# CY8C5888LTI_LP097 register map
File version: 0.1
Registers are 8-bit, read-write, no defined reset value unless marked. A register's access mark holds for its fields unless they carry their own. Offsets are from the block's base; [hi:lo] are bit positions; 'fields as' and 'values as' point back to an identical list.

## PWM_MOTORS
Base 0x00000000
0x40006428 PWM_MOTORS__COMPARE1 — UDB.D0 - Assigned Compare1 Value
0x40006438 PWM_MOTORS__COMPARE2 — UDB.D1 - Assigned Compare2 Value
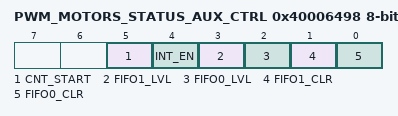
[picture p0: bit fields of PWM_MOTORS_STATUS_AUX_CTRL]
0x40006498 PWM_MOTORS_STATUS_AUX_CTRL — UDB Auxilliary Control Register
  [5] CNT_START — FIFO0 clear
    0=E_CNT_START0 (Disable counter); 1=E_CNT_START1 (Enable counter)
  [4] INT_EN
    0=E_INT_EN0 (Interrupt disabled); 1=E_INT_EN1 (Interrupt enabled)
  [3] FIFO1_LVL — FIFO level
    0=E_FIFO_LVL_0 (FIFO LVL: input mode: FIFO not full; output mode: FIFO not empty); 1=E_FIFO_LVL_1 (FIFO LVL: input mode: FIFO at least 1/2 empty; output mode: FIFO at least 1/2 full)
  [2] FIFO0_LVL — FIFO level
    values as FIFO1_LVL
  [1] FIFO1_CLR — FIFO1 clear
    0=E_FIFO_CLR_0 (Normal FIFO operation); 1=E_FIFO_CLR_1 (Clear FIFO state)
  [0] FIFO0_CLR — FIFO0 clear
    values as FIFO1_CLR

## BLINK_05HZ
Base 0x00000000
0x40006422 BLINK_05HZ_COMPARE_Reg 16-bit — UDB.D0 - Assigned Compare Value
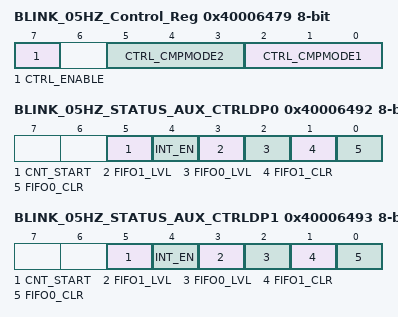
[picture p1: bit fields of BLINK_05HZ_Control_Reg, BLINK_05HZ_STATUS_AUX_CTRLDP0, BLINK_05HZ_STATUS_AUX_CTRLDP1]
0x40006479 BLINK_05HZ_Control_Reg — UDB Control Register - Assigned Control Register Value
  [7] CTRL_ENABLE — Enable the PWM
  [5:3] CTRL_CMPMODE2 — Compare mode 2
  [2:0] CTRL_CMPMODE1 — Compare mode 1
0x40006492 BLINK_05HZ_STATUS_AUX_CTRLDP0 — UDB Auxilliary Control Register
  [5] CNT_START — FIFO0 clear
    0=E_CNT_START0 (Disable counter); 1=E_CNT_START1 (Enable counter)
  [4] INT_EN
    0=E_INT_EN0 (Interrupt disabled); 1=E_INT_EN1 (Interrupt enabled)
  [3] FIFO1_LVL — FIFO level
    0=E_FIFO_LVL_0 (FIFO LVL: input mode: FIFO not full; output mode: FIFO not empty); 1=E_FIFO_LVL_1 (FIFO LVL: input mode: FIFO at least 1/2 empty; output mode: FIFO at least 1/2 full)
  [2] FIFO0_LVL — FIFO level
    values as FIFO1_LVL
  [1] FIFO1_CLR — FIFO1 clear
    0=E_FIFO_CLR_0 (Normal FIFO operation); 1=E_FIFO_CLR_1 (Clear FIFO state)
  [0] FIFO0_CLR — FIFO0 clear
    values as FIFO1_CLR
0x40006493 BLINK_05HZ_STATUS_AUX_CTRLDP1 — UDB Auxilliary Control Register
  fields as BLINK_05HZ_STATUS_AUX_CTRLDP0

## LED_CTRL
Base 0x00000000
0x40006575 LED_CTRL_CONTROL_REG

## CYCLES_TIMER
Base 0x00000000
0x400043A3 CYCLES_TIMER_GLOBAL_ENABLE — PM.ACT.CFG
  [3:0] en_timer — Enable timer/counters.
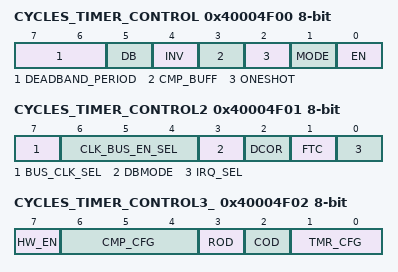
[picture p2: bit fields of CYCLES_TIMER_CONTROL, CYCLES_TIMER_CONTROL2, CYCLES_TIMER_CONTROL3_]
0x40004F00 CYCLES_TIMER_CONTROL — TMRx.CFG0
  [7:6] DEADBAND_PERIOD
  [5] DB — Deadband mode--Deadband phases phi1 and phi2 are outputted on CMP and TC output pins respectively.
    0=Timer (CMP and TC are output.); 1=Deadband (PHI1 (instead of CMP) and PHI2 (instead of TC) are output.)
  [4] INV — Invert sense of TIMEREN signal
  [3] CMP_BUFF — Buffer compare register. Compare register updates only on timer terminal count.
  [2] ONESHOT — Timer stops upon reaching stop condition defined by TMR_CFG bits. Can be restarted by asserting TIMER RESET or disabling and re-enabling block.
  [1] MODE — Mode. (0 = Timer; 1 = Comparator)
    0=Timer mode. CNT/CMP register holds timer count value.; 1=Comparator mode. CNT/CMP register holds comparator threshold value.
  [0] EN — Enables timer/comparator.
0x40004F01 CYCLES_TIMER_CONTROL2 — TMRx.CFG1
  [7] BUS_CLK_SEL — Bus Clock selection.
  [6:4] CLK_BUS_EN_SEL — Digital Global Clock selection.
  [3] DBMODE — Deadband mode (asynchronous/synchronous). CMP output pin is also affected when not in deadband mode (CFG0.DEADBAND).
  [2] DCOR — Disable Clear on Read (DCOR) of Status Register SR0.
  [1] FTC — First Terminal Count (FTC). Setting this bit forces a single pulse on the TC pin when first enabled.
    0=Disable_FTC (Disable the single cycle pulse, which signifies the timer is starting.); 1=Enable_FTC (Enable the single cycle pulse, which signifies the timer is starting.)
  [0] IRQ_SEL — Irq selection. (0 = raw interrupts; 1 = status register interrupts)
0x40004F02 CYCLES_TIMER_CONTROL3_ — TMRx.CFG2
  [7] HW_EN — When set Timer Enable controls counting.
  [6:4] CMP_CFG — Comparator configurations
    0=Equal (Compare Equal); 1=Less_than (Compare Less Than); 2=Less_than_or_equal (Compare Less Than or Equal .); 3=Greater (Compare Greater Than .); 4=Greater_than_or_equal (Compare Greater Than or Equal)
  [3] ROD — Reset On Disable (ROD). Resets internal state of output logic
  [2] COD — Clear On Disable (COD). Clears or gates outputs to zero.
  [1:0] TMR_CFG — Timer configuration (MODE = 0): 000 = Continuous; 001 = Pulsewidth; 010 = Period; 011 = Stop on IRQ
    0=Continuous (Timer runs while EN bit of CFG0 register is set to '1'.); 1=Pulsewidth (Timer runs from positive to negative edge of TIMEREN.); 2=Period (Timer runs from positive to positive edge of TIMEREN.); 3=Irq (Timer runs until IRQ.)
0x40004F04 CYCLES_TIMER_PERIOD 16-bit — TMRx.PER0 - Assigned Period
0x40004F06 CYCLES_TIMER_COUNTER 16-bit — TMRx.CNT_CMP0 - Current Down Counter Value
